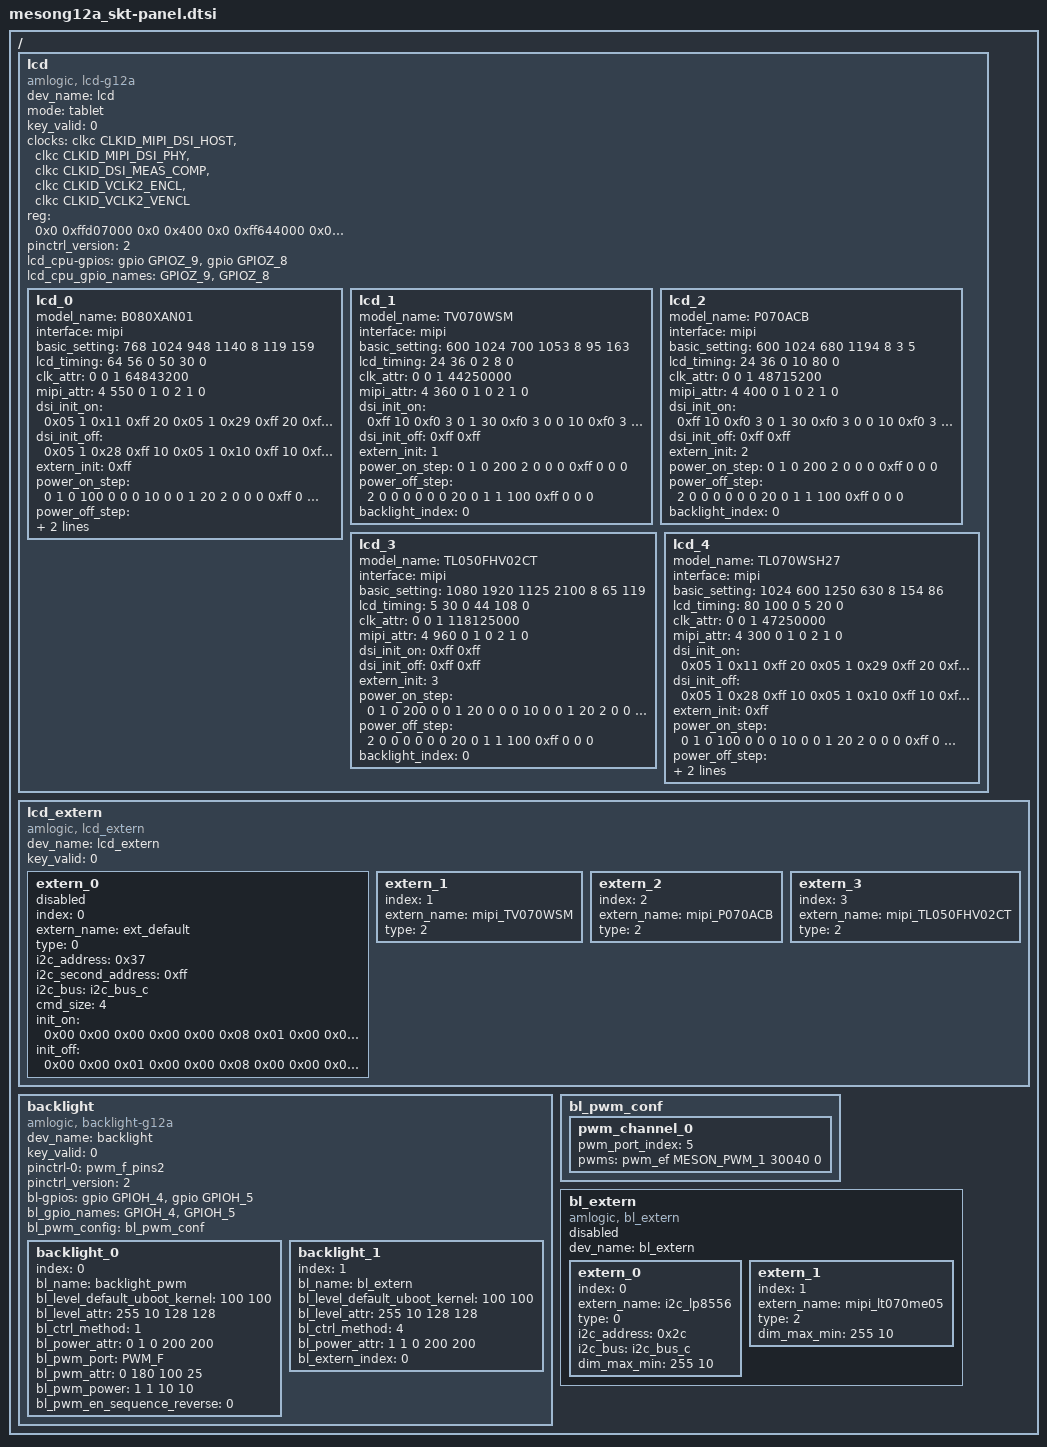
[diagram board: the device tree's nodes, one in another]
/*
 * arch/arm64/boot/dts/amlogic/mesongxm_q200-panel.dtsi
 *
 * Copyright (C) 2016 Amlogic, Inc. All rights reserved.
 *
 * This program is free software; you can redistribute it and/or modify
 * it under the terms of the GNU General Public License as published by
 * the Free Software Foundation; either version 2 of the License, or
 * (at your option) any later version.
 *
 * This program is distributed in the hope that it will be useful, but WITHOUT
 * ANY WARRANTY; without even the implied warranty of MERCHANTABILITY or
 * FITNESS FOR A PARTICULAR PURPOSE.  See the GNU General Public License for
 * more details.
 *
 */

/ {
	lcd{
		compatible = "amlogic, lcd-g12a";
		dev_name = "lcd";
		mode = "tablet";
		status = "okay";
		key_valid = <0>;
		clocks = <&clkc CLKID_MIPI_DSI_HOST
			&clkc CLKID_MIPI_DSI_PHY
			&clkc CLKID_DSI_MEAS_COMP
			&clkc CLKID_VCLK2_ENCL
			&clkc CLKID_VCLK2_VENCL>;
		clock-names = "dsi_host_gate",
			"dsi_phy_gate",
			"dsi_meas",
			"encl_top_gate",
			"encl_int_gate";
		reg = <0x0 0xffd07000 0x0 0x400
			   0x0 0xff644000 0x0 0x2000>;
		pinctrl_version = <2>; /* for uboot */

		/* power type:
		 *    (0=cpu_gpio, 1=pmu_gpio, 2=signal,3=extern, 0xff=ending)
		 * power index:
		 *    (point gpios_index, or extern_index,0xff=invalid)
		 * power value:(0=output low, 1=output high, 2=input)
		 * power delay:(unit in ms)
		 */
		lcd_cpu-gpios = <&gpio GPIOZ_9 GPIO_ACTIVE_HIGH
				&gpio GPIOZ_8 GPIO_ACTIVE_HIGH>;
		lcd_cpu_gpio_names = "GPIOZ_9","GPIOZ_8";

		lcd_0{
			model_name = "B080XAN01";
			interface = "mipi";
			basic_setting = <768 1024 /*h_active, v_active*/
				948 1140 /*h_period, v_period*/
				8 /*lcd_bits*/
				119 159>; /*screen_widht, screen_height*/
			lcd_timing = <64 56 0 /*hs_width, hs_bp, hs_pol*/
				50 30 0>; /*vs_width, vs_bp, vs_pol*/
			clk_attr = <0 /*fr_adj_type(0=clk, 1=htotal, 2=vtotal)*/
				0 /*clk_ss_level */
				1 /*clk_auto_generate*/
				64843200>; /*pixel_clk(unit in Hz)*/
			mipi_attr = <4 /*lane_num*/
				550 /*bit_rate_max(MHz)*/
				0 /*factor(*100, default 0 for auto)*/
				1 /*operation_mode_init(0=video, 1=command)*/
				0 /*operation_mode_display(0=video, 1=command)*/
				2 /*
				   *video_mode_type
				   *(0=sync_pulse,1=sync_event,2=burst)
				   */
				1 /*clk_lp_continuous(0=stop,1=continue)*/
				0>; /*phy_stop_wait(0=auto,1=standard,2=slow)*/

			/* dsi_init: data_type, num, data... */
			dsi_init_on = <0x05 1 0x11
					0xff 20     /*delay(ms)*/
					0x05 1 0x29
					0xff 20     /*delay(ms)*/
					0xff 0xff>; /*ending*/
			dsi_init_off = <0x05 1 0x28
					0xff 10     /*delay(ms)*/
					0x05 1 0x10
					0xff 10     /*delay(ms)*/
					0xff 0xff>; /*ending*/
			extern_init = <0xff>; /*0xff for invalid*/

			/* power step: type, index, value, delay(ms) */
			power_on_step = <
				0 1 0 100
				0 0 0 10
				0 0 1 20
				2 0 0 0
				0xff 0 0 0>; /*ending*/
			power_off_step = <
				2 0 0 50
				0 0 0 10
				0 1 1 100
				0xff 0 0 0>; /*ending*/
			backlight_index = <0>;
		};

		lcd_1{
			model_name = "TV070WSM";
			interface = "mipi";
			basic_setting = <600 1024 /*h_active, v_active*/
				700 1053 /*h_period, v_period*/
				8 /*lcd_bits*/
				95 163>; /*screen_widht, screen_height*/
			lcd_timing = <24 36 0 /*hs_width,hs_bp,hs_pol*/
				2 8 0>; /*vs_width,vs_bp,vs_pol*/
			clk_attr = <0 /*fr_adj_type(0=clock,1=htotal,2=vtotal)*/
				0 /*clk_ss_level*/
				1 /*clk_auto_generate*/
				44250000>; /*pixel_clk(unit in Hz)*/
			mipi_attr = <4 /*lane_num*/
				360 /*bit_rate_max(MHz)*/
				0 /*factor(*100, default 0 for auto)*/
				1 /*operation_mode_init(0=video, 1=command)*/
				0 /*operation_mode_display(0=video, 1=command)*/
				2 /*
				   *video_mode_type
				   *(0=sync_pulse,1=sync_event,2=burst)
				   */
				1 /*clk_lp_continuous(0=stop,1=continue)*/
				0>; /*phy_stop_wait(0=auto,1=standard,2=slow)*/
				/* dsi_init: data_type, num, data... */
			dsi_init_on = <
				0xff 10
				0xf0 3 0 1 30 /* reset high, delay 30ms */
				0xf0 3 0 0 10 /* reset low, delay 10ms */
				0xf0 3 0 1 30 /* reset high, delay 30ms */
				0xfc 2 0x04 3 /* check_reg, check_cnt */
				0xff 100   /* delay */
				0xff 0xff>; /* ending flag */
			dsi_init_off = <0xff 0xff>; /* ending flag */
				/* extern_init: 0xff for invalid */
			extern_init = <1>;
				/* power step: type,index,value,delay(ms) */
			power_on_step = <
					0 1 0 200
					2 0 0 0
					0xff 0 0 0>;
			power_off_step = <
					2 0 0 0
					0 0 0 20
					0 1 1 100
					0xff 0 0 0>;
			backlight_index = <0>;
		};

		lcd_2{
			model_name = "P070ACB";
			interface = "mipi";
			basic_setting = <600 1024 /*h_active, v_active*/
				680 1194 /*h_period, v_period*/
				8 /*lcd_bits*/
				3 5>; /*screen_widht, screen_height*/
			lcd_timing = <24 36 0 /*hs_width,hs_bp,hs_pol*/
				10 80 0>; /*vs_width,vs_bp,vs_pol*/
			clk_attr = <0 /*fr_adj_type(0=clock,1=htotal,2=vtotal)*/
				0 /*clk_ss_level*/
				1 /*clk_auto_generate*/
				48715200>; /*pixel_clk(unit in Hz)*/
			mipi_attr = <4 /*lane_num*/
				400 /*bit_rate_max(MHz)*/
				0 /*factor(*100, default 0 for auto)*/
				1 /*operation_mode_init(0=video, 1=command)*/
				0 /*operation_mode_display(0=video, 1=command)*/
				2 /*
				   *video_mode_type
				   *(0=sync_pulse,1=sync_event,2=burst)
				   */
				1 /*clk_lp_continuous(0=stop,1=continue)*/
				0>; /*phy_stop_wait(0=auto,1=standard,2=slow)*/
				/* dsi_init: data_type, num, data... */
			dsi_init_on = <
				0xff 10
				0xf0 3 0 1 30 /* reset high, delay 30ms */
				0xf0 3 0 0 10 /* reset low, delay 10ms */
				0xf0 3 0 1 30 /* reset high, delay 30ms */
				0xfc 2 0x04 3 /* check_reg, check_cnt */
				0xff 0xff>; /* ending flag */
			dsi_init_off = <0xff 0xff>; /* ending flag */
				/* extern_init: 0xff for invalid */
			extern_init = <2>;
				/* power step: type,index,value,delay(ms) */
			power_on_step = <
					0 1 0 200 /* panel power on */
					2 0 0 0
					0xff 0 0 0>;
			power_off_step = <
					2 0 0 0
					0 0 0 20  /* reset low */
					0 1 1 100 /* panel power off */
					0xff 0 0 0>;
			backlight_index = <0>;
		};

		lcd_3{
			model_name = "TL050FHV02CT";
			interface = "mipi";
			basic_setting = <1080 1920 /*h_active, v_active*/
				1125 2100 /*h_period, v_period*/
				8 /*lcd_bits*/
				65 119>; /*screen_widht, screen_height*/
			lcd_timing = <5 30 0 /*hs_width,hs_bp,hs_pol*/
				44 108 0>; /*vs_width,vs_bp,vs_pol*/
			clk_attr = <0 /*fr_adj_type(0=clock,1=htotal,2=vtotal)*/
				0 /*clk_ss_level*/
				1 /*clk_auto_generate*/
				118125000>; /*pixel_clk(unit in Hz)*/
			mipi_attr = <4 /*lane_num*/
				960 /*bit_rate_max(MHz)*/
				0 /*factor(*100, default 0 for auto)*/
				1 /*operation_mode_init(0=video, 1=command)*/
				0 /*operation_mode_display(0=video, 1=command)*/
				2 /*
				   *video_mode_type
				   *(0=sync_pulse,1=sync_event,2=burst)
				   */
				1 /*clk_lp_continuous(0=stop,1=continue)*/
				0>; /*phy_stop_wait(0=auto,1=standard,2=slow)*/
				/* dsi_init: data_type, num, data... */
			dsi_init_on = <0xff 0xff>; /* ending flag */
			dsi_init_off = <0xff 0xff>; /* ending flag */
				/* extern_init: 0xff for invalid */
			extern_init = <3>;
				/* power step: type,index,value,delay(ms) */
			power_on_step = <
					0 1 0 200
					0 0 1 20
					0 0 0 10
					0 0 1 20
					2 0 0 0
					0xff 0 0 0>;
			power_off_step = <
					2 0 0 0
					0 0 0 20
					0 1 1 100
					0xff 0 0 0>;
			backlight_index = <0>;
		};

		lcd_4{
			model_name = "TL070WSH27";
			interface = "mipi";
			basic_setting = <1024 600 /*h_active, v_active*/
				1250 630 /*h_period, v_period*/
				8 /*lcd_bits*/
				154 86>; /*screen_widht, screen_height*/
			lcd_timing = <80 100 0 /*hs_width, hs_bp, hs_pol*/
				5 20 0>; /*vs_width, vs_bp, vs_pol*/
			clk_attr = <0 /*fr_adj_type(0=clk, 1=htotal, 2=vtotal)*/
				0 /*clk_ss_level */
				1 /*clk_auto_generate*/
				47250000>; /*pixel_clk(unit in Hz)*/
			mipi_attr = <4 /*lane_num*/
				300 /*bit_rate_max(MHz)*/
				0 /*factor(*100, default 0 for auto)*/
				1 /*operation_mode_init(0=video, 1=command)*/
				0 /*operation_mode_display(0=video, 1=command)*/
				2 /*
				   *video_mode_type
				   *(0=sync_pulse,1=sync_event,2=burst)
				   */
				1 /*clk_lp_continuous(0=stop,1=continue)*/
				0>; /*phy_stop_wait(0=auto,1=standard,2=slow)*/

			/* dsi_init: data_type, num, data... */
			dsi_init_on = <0x05 1 0x11
					0xff 20     /*delay(ms)*/
					0x05 1 0x29
					0xff 20     /*delay(ms)*/
					0xff 0xff>; /*ending*/
			dsi_init_off = <0x05 1 0x28
					0xff 10     /*delay(ms)*/
					0x05 1 0x10
					0xff 10     /*delay(ms)*/
					0xff 0xff>; /*ending*/
			extern_init = <0xff>; /*0xff for invalid*/

			/* power step: type, index, value, delay(ms) */
			power_on_step = <
				0 1 0 100
				0 0 0 10
				0 0 1 20
				2 0 0 0
				0xff 0 0 0>; /*ending*/
			power_off_step = <
				2 0 0 50
				0 0 0 10
				0 1 1 100
				0xff 0 0 0>; /*ending*/
			backlight_index = <0>;
		};
	};

	lcd_extern{
		compatible = "amlogic, lcd_extern";
		dev_name = "lcd_extern";
		status = "okay";
		key_valid = <0>;

		extern_0{
			index = <0>;
			extern_name = "ext_default";
			status = "disabled";
			type = <0>; /*0=i2c, 1=spi, 2=mipi*/
			i2c_address = <0x37>; /*7bit i2c address*/
			i2c_second_address = <0xff>; /*0xff for none*/
			i2c_bus = "i2c_bus_c";
			cmd_size = <4>;

			/* init on/off: (type, value..., delay),
			 * must match cmd_size for every group
			 * type: 0x00=cmd(bit[3:0]=1 for second_addr),
			 *		0xf0=gpio, 0xff=ending
			 * value: i2c or spi cmd, or gpio index & level,
			 *		fill 0x0 for no use
			 * delay: unit ms
			 */
			init_on = <0x00 0x00 0x00 0x00
				0x00 0x08 0x01 0x00
				0x00 0x10 0x3F 0x00
				0x00 0x11 0x00 0x00
				0x00 0x12 0x00 0x00
				0x00 0x13 0xE4 0x00
				0x00 0x14 0x02 0x00
				0x00 0x15 0x02 0x00
				0x00 0x16 0x24 0x00
				0x00 0x17 0x00 0x00
				0x00 0x18 0x21 0x00
				0x00 0x20 0x3F 0x00
				0x00 0x21 0xFF 0x00
				0x00 0x22 0x00 0x00
				0x00 0x23 0x00 0x00
				0x00 0x24 0x00 0x00
				0x00 0x25 0x00 0x00
				0x00 0x26 0xE4 0x00
				0x00 0x27 0x00 0x00
				0x00 0x28 0x28 0x00
				0x00 0x29 0x01 0x00
				0x00 0x2A 0x00 0x00
				0x00 0x2B 0x01 0x00
				0x00 0x2C 0x0E 0x00
				0x00 0x2D 0x00 0x00
				0x00 0x2E 0x18 0x00
				0x00 0x2F 0x02 0x00
				0x00 0x30 0x02 0x00
				0x00 0x31 0x00 0x00
				0x00 0x32 0x63 0x00
				0x00 0x40 0x00 0x00
				0x00 0x41 0x00 0x00
				0x00 0x42 0x00 0x00
				0x00 0x12 0x00 0x00
				0x00 0x13 0xE4 0x00
				0x00 0x14 0x02 0x00
				0x00 0x15 0x00 0x00
				0x00 0x16 0x0D 0x00
				0x00 0x17 0x00 0x00
				0x00 0x18 0x21 0x00
				0x00 0x41 0x06 0x00
				0x00 0x00 0x01 0x00
				0x00 0x08 0x00 0x00
				0x00 0x10 0x00 0x00
				0x00 0x11 0x0F 0x00
				0xff 0x00 0x00 0x00>; /*ending*/
			init_off = <0x00 0x00 0x01 0x00
				0x00 0x08 0x00 0x00
				0x00 0x10 0x00 0x00
				0x00 0x11 0x0F 0x00
				0xff 0x00 0x00 0x00>; /*ending*/
		};

		extern_1{
			index = <1>;
			extern_name = "mipi_TV070WSM";
			status = "okay";
			type = <2>; /* 0=i2c, 1=spi, 2=mipi */
		};

		extern_2{
			index = <2>;
			extern_name = "mipi_P070ACB";
			status = "okay";
			type = <2>; /* 0=i2c, 1=spi, 2=mipi */
		};

		extern_3{
			index = <3>;
			extern_name = "mipi_TL050FHV02CT";
			status = "okay";
			type = <2>; /* 0=i2c, 1=spi, 2=mipi */
		};
	};

	backlight{
		compatible = "amlogic, backlight-g12a";
		dev_name = "backlight";
		status = "okay";
		key_valid = <0>;
		pinctrl-names = "pwm_on";
		pinctrl-0 = <&pwm_f_pins2>;
		pinctrl_version = <2>; /* for uboot */
		/* pwm port: PWM_A, PWM_B, PWM_C, PWM_D, PWM_E, PWM_F, PWM_VS*/
		/* power index:(point gpios_index, 0xff=invalid)
		 * power value:(0=output low, 1=output high, 2=input)
		 * power delay:(unit in ms)
		 */
		bl-gpios = <&gpio GPIOH_4 GPIO_ACTIVE_HIGH
			&gpio GPIOH_5 GPIO_ACTIVE_HIGH>;
		bl_gpio_names = "GPIOH_4","GPIOH_5";
		bl_pwm_config = <&bl_pwm_conf>;
		backlight_0{
			index = <0>;
			bl_name = "backlight_pwm";
			bl_level_default_uboot_kernel = <100 100>;
			bl_level_attr = <255 10 /*max, min*/
				128 128>; /*mid, mid_mapping*/
			bl_ctrl_method = <1>; /* 1=pwm, 2=pwm_combo, 4=extern */
			bl_power_attr = <0 /*en_gpio_index*/
				1 0 /*on_value, off_value*/
				200 200>; /*on_delay(ms), off_delay(ms)*/
			bl_pwm_port = "PWM_F";
			bl_pwm_attr = <0 /*pwm_method*/
				180 /*pwm_freq(pwm:Hz, pwm_vs:multiple of vs)*/
				100 25>; /*duty_max(%), duty_min(%)*/
			bl_pwm_power = <1 1 /*pwm_gpio_index, pwm_gpio_off*/
				10 10>; /*pwm_on_delay(ms), pwm_off_delay(ms)*/
			bl_pwm_en_sequence_reverse = <0>; /* 1 for reverse */
		};
		backlight_1{
			index = <1>;
			bl_name = "bl_extern";
			bl_level_default_uboot_kernel = <100 100>;
			bl_level_attr = <255 10 /*max, min*/
				128 128>; /*mid, mid_mapping*/
			bl_ctrl_method = <4>; /*1=pwm, 2=pwm_combo, 4=extern*/
			bl_power_attr = <1 /*en_gpio_index*/
				1 0 /*on_value, off_value*/
				200 200>; /*on_delay(ms), off_delay(ms)*/
			bl_extern_index = <0>;
		};
	};
	bl_pwm_conf:bl_pwm_conf{
		pwm_channel_0 {
			pwm_port_index = <5>;
			pwms = <&pwm_ef MESON_PWM_1 30040 0>;
		};
	};
	bl_extern{
		compatible = "amlogic, bl_extern";
		dev_name = "bl_extern";
		status = "disabled";
		extern_0{
			index = <0>;
			extern_name = "i2c_lp8556";
			type = <0>; /*0=i2c, 1=spi, 2=mipi*/
			i2c_address = <0x2c>; /*7bit i2c address*/
			i2c_bus = "i2c_bus_c";
			dim_max_min = <255 10>;
		};
		extern_1{
			index = <1>;
			extern_name = "mipi_lt070me05";
			type = <2>; /*0=i2c, 1=spi, 2=mipi*/
			dim_max_min = <255 10>;
		};
	};
};/* end of panel */

